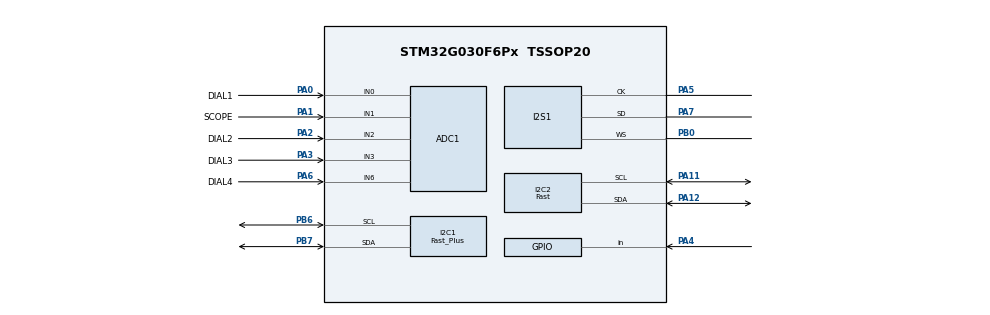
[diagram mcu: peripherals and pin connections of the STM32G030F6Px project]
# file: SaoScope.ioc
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ADC1.ClockPrescaler=ADC_CLOCK_ASYNC_DIV2
ADC1.ContinuousConvMode=ENABLE
ADC1.DMAContinuousRequests=ENABLE
ADC1.EnableAnalogWatchDog1=true
ADC1.EnableAnalogWatchDog2=true
ADC1.NbrOfConversion=1
ADC1.NbrOfConversionFlag=0
ADC1.SamplingTimeCommon1=ADC_SAMPLETIME_7CYCLES_5
ADC1.SelectedChannel=ADC_CHANNEL_0|ADC_CHANNEL_1|ADC_CHANNEL_2|ADC_CHANNEL_3|ADC_CHANNEL_6|ADC_CHANNEL_VREFINT
ADC1.Sequencer=NOT_FULLY_CONFIGURABLE
ADC1.WatchdogChannel=ADC_CHANNEL_1
ADC1.master=1
Dma.ADC1.0.Direction=DMA_PERIPH_TO_MEMORY
Dma.ADC1.0.EventEnable=DISABLE
Dma.ADC1.0.Instance=DMA1_Channel1
Dma.ADC1.0.MemDataAlignment=DMA_MDATAALIGN_HALFWORD
Dma.ADC1.0.MemInc=DMA_MINC_ENABLE
Dma.ADC1.0.Mode=DMA_CIRCULAR
Dma.ADC1.0.PeriphDataAlignment=DMA_PDATAALIGN_HALFWORD
Dma.ADC1.0.PeriphInc=DMA_PINC_DISABLE
Dma.ADC1.0.Polarity=HAL_DMAMUX_REQ_GEN_RISING
Dma.ADC1.0.Priority=DMA_PRIORITY_LOW
Dma.ADC1.0.RequestNumber=1
Dma.ADC1.0.SignalID=NONE
Dma.ADC1.0.SyncEnable=DISABLE
Dma.ADC1.0.SyncPolarity=HAL_DMAMUX_SYNC_NO_EVENT
Dma.ADC1.0.SyncRequestNumber=1
Dma.ADC1.0.SyncSignalID=NONE
Dma.Request0=ADC1
I2C1.I2C_Speed_Mode=I2C_Fast_Plus
I2C1.Timing=0x00200923
I2C2.I2C_Speed_Mode=I2C_Fast
I2C2.OwnAddress=89
I2C2.Timing=0x00501D63
I2S1.AudioFreq=I2S_AUDIOFREQ_192K
I2S1.DataFormat=I2S_DATAFORMAT_32B
I2S1.ErrorAudioFreq=-8.85 %
I2S1.FullDuplexMode=I2S_FULLDUPLEXMODE_DISABLE
I2S1.Instance=SPI$Index
I2S1.Mode=I2S_MODE_MASTER_RX
I2S1.RealAudioFreq=175.0 KHz
I2S1.VirtualMode=I2S_MODE_MASTER
Mcu.Family=STM32G0
Mcu.Name=STM32G030F6Px
Mcu.Package=TSSOP20
NVIC.DMA1_Channel1_IRQn=true\:0\:0\:false\:false\:true\:false\:true\:true
NVIC.RTC_TAMP_IRQn=true\:0\:0\:false\:false\:true\:true\:true\:true
PA0.GPIO_Label=DIAL1
PA0.Mode=IN0
PA0.Signal=ADC1_IN0
PA1.GPIO_Label=SCOPE
PA1.Mode=IN1
PA1.Signal=ADC1_IN1
PA11\ [PA9].Mode=I2C
PA11\ [PA9].Signal=I2C2_SCL
PA12\ [PA10].Mode=I2C
PA12\ [PA10].Signal=I2C2_SDA
PA13.Mode=Serial_Wire
PA13.Signal=SYS_SWDIO
PA14-BOOT0.Mode=Serial_Wire
PA14-BOOT0.Signal=SYS_SWCLK
PA14-BOOT0__PA15.StandardMode=true
PA2.GPIO_Label=DIAL2
PA2.Mode=IN2
PA2.Signal=ADC1_IN2
PA3.GPIO_Label=DIAL3
PA3.Mode=IN3
PA3.Signal=ADC1_IN3
PA4.Signal=GPIO_Input
PA5.Mode=Half_Duplex_Master
PA5.Signal=I2S1_CK
PA6.GPIO_Label=DIAL4
PA6.Mode=IN6
PA6.Signal=ADC1_IN6
PA7.GPIO_Speed=GPIO_SPEED_FREQ_VERY_HIGH
PA7.Signal=SharedStack_PA7
PA7.Stacked=true
PB0.Mode=Half_Duplex_Master
PB0.Signal=I2S1_WS
PB0__PB1__PB2__PA8.StandardMode=true
PB3__PB4__PB5__PB6.StandardMode=true
PB6.GPIO_FM6=SYSCFG_FASTMODEPLUS_PB6
PB6.GPIO_Speed=GPIO_SPEED_FREQ_VERY_HIGH
PB6.Mode=I2C
PB6.Signal=I2C1_SCL
PB7.GPIO_FM7=SYSCFG_FASTMODEPLUS_PB7
PB7.GPIO_Speed=GPIO_SPEED_FREQ_VERY_HIGH
PB7.Mode=I2C
PB7.Signal=I2C1_SDA
PB7__PB8.StandardMode=true
PC14-OSC32_IN\ (PC14).Mode=LSE-External-Oscillator
PC14-OSC32_IN\ (PC14).Signal=RCC_OSC32_IN
PC14-OSC32_IN\ (PC14)__PB9.StandardMode=true
PC15-OSC32_OUT\ (PC15).Mode=LSE-External-Oscillator
PC15-OSC32_OUT\ (PC15).Signal=RCC_OSC32_OUT
ProjectManager.HeapSize=0x000
ProjectManager.StackSize=0x400
ProjectManager.TargetToolchain=CMake
RCC.ADCCLockSelection=RCC_ADCCLKSOURCE_PLLADC
RCC.ADCFreq_Value=70000000
RCC.AHBFreq_Value=56000000
RCC.CortexFreq_Value=56000000
RCC.EXTERNAL_CLOCK_VALUE=12288000
RCC.HCLKFreq_Value=56000000
RCC.HSE_VALUE=8000000
RCC.HSI_VALUE=16000000
RCC.PLLM=RCC_PLLM_DIV4
RCC.PLLN=70
RCC.PLLP=RCC_PLLP_DIV4
RCC.PLLR=RCC_PLLR_DIV5
RCC.RTCClockSelection=RCC_RTCCLKSOURCE_LSE
RCC.SYSCLKFreq_VALUE=56000000
RCC.SYSCLKSource=RCC_SYSCLKSOURCE_PLLCLK
RCC.VCOOutputFreq_Value=280000000
RCC.VDD_VALUE=3
RTC.WakeUpClock-WakeUp=RTC_WAKEUPCLOCK_CK_SPRE_16BITS
RTC.WakeUpCounter-WakeUp=1
SH.SharedStack_PA7.0=TIM17_CH1
SH.SharedStack_PA7.1=I2S1_SD,Half_Duplex_Master
TIM17.Channel=TIM_CHANNEL_1
VP_ADC1_Vref_Input.Mode=IN-Vrefint
VP_RTC_VS_RTC_Activate.Mode=RTC_Enabled
VP_RTC_VS_RTC_WakeUp_intern.Mode=WakeUp
VP_TIM14_VS_ClockSourceINT.Mode=Enable_Timer
VP_TIM16_VS_ClockSourceINT.Mode=Enable_Timer
VP_TIM17_VS_ClockSourceINT.Mode=Enable_Timer
VP_TIM1_VS_ClockSourceINT.Mode=Internal
VP_TIM3_VS_ClockSourceINT.Mode=Internal
board=custom

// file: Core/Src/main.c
/* USER CODE BEGIN Header */
/**
  ******************************************************************************
  * @file           : main.c
  * @brief          : Main program body
  ******************************************************************************
  * @attention
  *
  * Copyright (c) 2022 STMicroelectronics.
  * All rights reserved.
  *
  * This software is licensed under terms that can be found in the LICENSE file
  * in the root directory of this software component.
  * If no LICENSE file comes with this software, it is provided AS-IS.
  *
  ******************************************************************************
  */
/* USER CODE END Header */
#include "main.h"

/* USER CODE BEGIN Includes */

void run();

/* USER CODE END Includes */

void SystemClock_Config(void);
static void MX_GPIO_Init(void);
static void MX_DMA_Init(void);
static void MX_ADC1_Init(void);
static void MX_I2C1_Init(void);
static void MX_I2C2_Init(void);
static void MX_RTC_Init(void);
static void MX_TIM1_Init(void);
static void MX_TIM3_Init(void);
static void MX_TIM14_Init(void);
static void MX_TIM16_Init(void);
static void MX_TIM17_Init(void);
static void MX_I2S1_Init(void);

int main(void)
{

  /* MCU Configuration--------------------------------------------------------*/

  /* Reset of all peripherals, Initializes the Flash interface and the Systick. */
  LL_APB2_GRP1_EnableClock(LL_APB2_GRP1_PERIPH_SYSCFG);
  LL_APB1_GRP1_EnableClock(LL_APB1_GRP1_PERIPH_PWR);

  /* SysTick_IRQn interrupt configuration */
  NVIC_SetPriority(SysTick_IRQn, 3);

  /* Configure the system clock */
  SystemClock_Config();

  /* Initialize all configured peripherals */
  MX_GPIO_Init();
  MX_DMA_Init();
  MX_ADC1_Init();
  MX_I2C1_Init();
  MX_I2C2_Init();
  MX_RTC_Init();
  MX_TIM1_Init();
  MX_TIM3_Init();
  MX_TIM14_Init();
  MX_TIM16_Init();
  MX_TIM17_Init();
  MX_I2S1_Init();

  /* Infinite loop */
  /* USER CODE BEGIN WHILE */
  run();
    /* USER CODE END WHILE */

}

void SystemClock_Config(void)
{
  LL_FLASH_SetLatency(LL_FLASH_LATENCY_2);
  while(LL_FLASH_GetLatency() != LL_FLASH_LATENCY_2)
  {
  }

  /* HSI configuration and activation */
  LL_RCC_HSI_Enable();
  while(LL_RCC_HSI_IsReady() != 1)
  {
  }

  LL_PWR_EnableBkUpAccess();
  /* LSE configuration and activation */
  LL_RCC_LSE_SetDriveCapability(LL_RCC_LSEDRIVE_LOW);
  LL_RCC_LSE_Enable();
  while(LL_RCC_LSE_IsReady() != 1)
  {
  }

  /* Main PLL configuration and activation */
  LL_RCC_PLL_ConfigDomain_ADC(LL_RCC_PLLSOURCE_HSI, LL_RCC_PLLM_DIV_4, 70, LL_RCC_PLLP_DIV_4);
  LL_RCC_PLL_EnableDomain_ADC();
  LL_RCC_PLL_ConfigDomain_SYS(LL_RCC_PLLSOURCE_HSI, LL_RCC_PLLM_DIV_4, 70, LL_RCC_PLLR_DIV_5);
  LL_RCC_PLL_Enable();
  LL_RCC_PLL_EnableDomain_SYS();
  while(LL_RCC_PLL_IsReady() != 1)
  {
  }

  /* Set AHB prescaler*/
  LL_RCC_SetAHBPrescaler(LL_RCC_SYSCLK_DIV_1);

  /* Sysclk activation on the main PLL */
  LL_RCC_SetSysClkSource(LL_RCC_SYS_CLKSOURCE_PLL);
  while(LL_RCC_GetSysClkSource() != LL_RCC_SYS_CLKSOURCE_STATUS_PLL)
  {
  }

  /* Set APB1 prescaler*/
  LL_RCC_SetAPB1Prescaler(LL_RCC_APB1_DIV_1);

  LL_Init1msTick(56000000);

  /* Update CMSIS variable (which can be updated also through SystemCoreClockUpdate function) */
  LL_SetSystemCoreClock(56000000);
}

static void MX_ADC1_Init(void)
{

  LL_ADC_InitTypeDef ADC_InitStruct = {0};
  LL_ADC_REG_InitTypeDef ADC_REG_InitStruct = {0};

  LL_GPIO_InitTypeDef GPIO_InitStruct = {0};

  LL_RCC_SetADCClockSource(LL_RCC_ADC_CLKSOURCE_PLL);

  /* Peripheral clock enable */
  LL_APB2_GRP1_EnableClock(LL_APB2_GRP1_PERIPH_ADC);

  LL_IOP_GRP1_EnableClock(LL_IOP_GRP1_PERIPH_GPIOA);
  /**ADC1 GPIO Configuration
  PA0   ------> ADC1_IN0
  PA1   ------> ADC1_IN1
  PA2   ------> ADC1_IN2
  PA3   ------> ADC1_IN3
  PA6   ------> ADC1_IN6
  */
  GPIO_InitStruct.Pin = DIAL1_Pin;
  GPIO_InitStruct.Mode = LL_GPIO_MODE_ANALOG;
  GPIO_InitStruct.Pull = LL_GPIO_PULL_NO;
  LL_GPIO_Init(DIAL1_GPIO_Port, &GPIO_InitStruct);

  GPIO_InitStruct.Pin = SCOPE_Pin;
  GPIO_InitStruct.Mode = LL_GPIO_MODE_ANALOG;
  GPIO_InitStruct.Pull = LL_GPIO_PULL_NO;
  LL_GPIO_Init(SCOPE_GPIO_Port, &GPIO_InitStruct);

  GPIO_InitStruct.Pin = DIAL2_Pin;
  GPIO_InitStruct.Mode = LL_GPIO_MODE_ANALOG;
  GPIO_InitStruct.Pull = LL_GPIO_PULL_NO;
  LL_GPIO_Init(DIAL2_GPIO_Port, &GPIO_InitStruct);

  GPIO_InitStruct.Pin = DIAL3_Pin;
  GPIO_InitStruct.Mode = LL_GPIO_MODE_ANALOG;
  GPIO_InitStruct.Pull = LL_GPIO_PULL_NO;
  LL_GPIO_Init(DIAL3_GPIO_Port, &GPIO_InitStruct);

  GPIO_InitStruct.Pin = DIAL4_Pin;
  GPIO_InitStruct.Mode = LL_GPIO_MODE_ANALOG;
  GPIO_InitStruct.Pull = LL_GPIO_PULL_NO;
  LL_GPIO_Init(DIAL4_GPIO_Port, &GPIO_InitStruct);

  /* ADC1 DMA Init */

  /* ADC1 Init */
  LL_DMA_SetPeriphRequest(DMA1, LL_DMA_CHANNEL_1, LL_DMAMUX_REQ_ADC1);

  LL_DMA_SetDataTransferDirection(DMA1, LL_DMA_CHANNEL_1, LL_DMA_DIRECTION_PERIPH_TO_MEMORY);

  LL_DMA_SetChannelPriorityLevel(DMA1, LL_DMA_CHANNEL_1, LL_DMA_PRIORITY_LOW);

  LL_DMA_SetMode(DMA1, LL_DMA_CHANNEL_1, LL_DMA_MODE_CIRCULAR);

  LL_DMA_SetPeriphIncMode(DMA1, LL_DMA_CHANNEL_1, LL_DMA_PERIPH_NOINCREMENT);

  LL_DMA_SetMemoryIncMode(DMA1, LL_DMA_CHANNEL_1, LL_DMA_MEMORY_INCREMENT);

  LL_DMA_SetPeriphSize(DMA1, LL_DMA_CHANNEL_1, LL_DMA_PDATAALIGN_HALFWORD);

  LL_DMA_SetMemorySize(DMA1, LL_DMA_CHANNEL_1, LL_DMA_MDATAALIGN_HALFWORD);

  /** Configure the global features of the ADC (Clock, Resolution, Data Alignment and number of conversion)
  */

   #define ADC_CHANNEL_CONF_RDY_TIMEOUT_MS ( 1U)
   #if (USE_TIMEOUT == 1)
   uint32_t Timeout ; /* Variable used for Timeout management */
   #endif /* USE_TIMEOUT */

  ADC_InitStruct.Resolution = LL_ADC_RESOLUTION_12B;
  ADC_InitStruct.DataAlignment = LL_ADC_DATA_ALIGN_RIGHT;
  ADC_InitStruct.LowPowerMode = LL_ADC_LP_MODE_NONE;
  LL_ADC_Init(ADC1, &ADC_InitStruct);
  LL_ADC_REG_SetSequencerConfigurable(ADC1, LL_ADC_REG_SEQ_FIXED);
  ADC_REG_InitStruct.TriggerSource = LL_ADC_REG_TRIG_SOFTWARE;
  ADC_REG_InitStruct.SequencerLength = LL_ADC_REG_SEQ_SCAN_DISABLE;
  ADC_REG_InitStruct.ContinuousMode = LL_ADC_REG_CONV_CONTINUOUS;
  ADC_REG_InitStruct.DMATransfer = LL_ADC_REG_DMA_TRANSFER_UNLIMITED;
  ADC_REG_InitStruct.Overrun = LL_ADC_REG_OVR_DATA_PRESERVED;
  LL_ADC_REG_Init(ADC1, &ADC_REG_InitStruct);
  LL_ADC_SetCommonClock(__LL_ADC_COMMON_INSTANCE(ADC1), LL_ADC_CLOCK_ASYNC_DIV2);
  LL_ADC_REG_SetSequencerScanDirection(ADC1, LL_ADC_REG_SEQ_SCAN_DIR_FORWARD);
  LL_ADC_SetOverSamplingScope(ADC1, LL_ADC_OVS_DISABLE);
  LL_ADC_SetTriggerFrequencyMode(ADC1, LL_ADC_CLOCK_FREQ_MODE_HIGH);
  LL_ADC_REG_SetSequencerChAdd(ADC1, LL_ADC_CHANNEL_0|LL_ADC_CHANNEL_1
                              |LL_ADC_CHANNEL_2|LL_ADC_CHANNEL_3
                              |LL_ADC_CHANNEL_6|LL_ADC_CHANNEL_VREFINT);

   /* Poll for ADC channel configuration ready */
   #if (USE_TIMEOUT == 1)
   Timeout = ADC_CHANNEL_CONF_RDY_TIMEOUT_MS;
   #endif /* USE_TIMEOUT */
   while (LL_ADC_IsActiveFlag_CCRDY(ADC1) == 0)
     {
   #if (USE_TIMEOUT == 1)
   /* Check Systick counter flag to decrement the time-out value */
   if (LL_SYSTICK_IsActiveCounterFlag())
     {
   if(Timeout-- == 0)
         {
   Error_Handler();
         }
     }
   #endif /* USE_TIMEOUT */
     }
   /* Clear flag ADC channel configuration ready */
   LL_ADC_ClearFlag_CCRDY(ADC1);
  LL_ADC_SetCommonPathInternalCh(__LL_ADC_COMMON_INSTANCE(ADC1), LL_ADC_AWD_CH_VREFINT_REG);
  LL_ADC_SetSamplingTimeCommonChannels(ADC1, LL_ADC_SAMPLINGTIME_COMMON_1, LL_ADC_SAMPLINGTIME_7CYCLES_5);
  LL_ADC_DisableIT_EOC(ADC1);
  LL_ADC_DisableIT_EOS(ADC1);

   /* Enable ADC internal voltage regulator */
   LL_ADC_EnableInternalRegulator(ADC1);
   /* Delay for ADC internal voltage regulator stabilization. */
   /* Compute number of CPU cycles to wait for, from delay in us. */
   /* Note: Variable divided by 2 to compensate partially */
   /* CPU processing cycles (depends on compilation optimization). */
   /* Note: If system core clock frequency is below 200kHz, wait time */
   /* is only a few CPU processing cycles. */
   uint32_t wait_loop_index;
   wait_loop_index = ((LL_ADC_DELAY_INTERNAL_REGUL_STAB_US * (SystemCoreClock / (100000 * 2))) / 10);
   while(wait_loop_index != 0)
     {
   wait_loop_index--;
     }

  /** Configure Analog WatchDog 1
  */
  LL_ADC_SetAnalogWDMonitChannels(ADC1, LL_ADC_AWD1, LL_ADC_AWD_CHANNEL_1_REG);
  LL_ADC_ConfigAnalogWDThresholds(ADC1, LL_ADC_AWD1, 0, 0);
  LL_ADC_DisableIT_AWD1(ADC1);

  /** Configure the regular channel to be monitored by WatchDog 2
  */
  LL_ADC_ConfigAnalogWDThresholds(ADC1, LL_ADC_AWD2, 0, 0);
  LL_ADC_DisableIT_AWD2(ADC1);

}

static void MX_I2C1_Init(void)
{

  LL_I2C_InitTypeDef I2C_InitStruct = {0};

  LL_GPIO_InitTypeDef GPIO_InitStruct = {0};

  LL_RCC_SetI2CClockSource(LL_RCC_I2C1_CLKSOURCE_PCLK1);

  LL_IOP_GRP1_EnableClock(LL_IOP_GRP1_PERIPH_GPIOB);
  /**I2C1 GPIO Configuration
  PB7   ------> I2C1_SDA
  PB6   ------> I2C1_SCL
  */
  GPIO_InitStruct.Pin = LL_GPIO_PIN_7;
  GPIO_InitStruct.Mode = LL_GPIO_MODE_ALTERNATE;
  GPIO_InitStruct.Speed = LL_GPIO_SPEED_FREQ_VERY_HIGH;
  GPIO_InitStruct.OutputType = LL_GPIO_OUTPUT_OPENDRAIN;
  GPIO_InitStruct.Pull = LL_GPIO_PULL_NO;
  GPIO_InitStruct.Alternate = LL_GPIO_AF_6;
  LL_GPIO_Init(GPIOB, &GPIO_InitStruct);

  GPIO_InitStruct.Pin = LL_GPIO_PIN_6;
  GPIO_InitStruct.Mode = LL_GPIO_MODE_ALTERNATE;
  GPIO_InitStruct.Speed = LL_GPIO_SPEED_FREQ_VERY_HIGH;
  GPIO_InitStruct.OutputType = LL_GPIO_OUTPUT_OPENDRAIN;
  GPIO_InitStruct.Pull = LL_GPIO_PULL_NO;
  GPIO_InitStruct.Alternate = LL_GPIO_AF_6;
  LL_GPIO_Init(GPIOB, &GPIO_InitStruct);

  LL_SYSCFG_EnableFastModePlus(LL_SYSCFG_I2C_FASTMODEPLUS_PB7);

  LL_SYSCFG_EnableFastModePlus(LL_SYSCFG_I2C_FASTMODEPLUS_PB6);

  /* Peripheral clock enable */
  LL_APB1_GRP1_EnableClock(LL_APB1_GRP1_PERIPH_I2C1);

  /** I2C Initialization
  */
  I2C_InitStruct.PeripheralMode = LL_I2C_MODE_I2C;
  I2C_InitStruct.Timing = 0x00200923;
  I2C_InitStruct.AnalogFilter = LL_I2C_ANALOGFILTER_ENABLE;
  I2C_InitStruct.DigitalFilter = 0;
  I2C_InitStruct.OwnAddress1 = 0;
  I2C_InitStruct.TypeAcknowledge = LL_I2C_ACK;
  I2C_InitStruct.OwnAddrSize = LL_I2C_OWNADDRESS1_7BIT;
  LL_I2C_Init(I2C1, &I2C_InitStruct);
  LL_I2C_EnableAutoEndMode(I2C1);
  LL_I2C_SetOwnAddress2(I2C1, 0, LL_I2C_OWNADDRESS2_NOMASK);
  LL_I2C_DisableOwnAddress2(I2C1);
  LL_I2C_DisableGeneralCall(I2C1);
  LL_I2C_EnableClockStretching(I2C1);

  /** I2C Fast mode Plus enable
  */
  LL_SYSCFG_EnableFastModePlus(LL_SYSCFG_I2C_FASTMODEPLUS_I2C1);

}

static void MX_I2C2_Init(void)
{

  LL_I2C_InitTypeDef I2C_InitStruct = {0};

  LL_GPIO_InitTypeDef GPIO_InitStruct = {0};

  LL_IOP_GRP1_EnableClock(LL_IOP_GRP1_PERIPH_GPIOA);
  /**I2C2 GPIO Configuration
  PA11 [PA9]   ------> I2C2_SCL
  PA12 [PA10]   ------> I2C2_SDA
  */
  GPIO_InitStruct.Pin = LL_GPIO_PIN_11;
  GPIO_InitStruct.Mode = LL_GPIO_MODE_ALTERNATE;
  GPIO_InitStruct.Speed = LL_GPIO_SPEED_FREQ_LOW;
  GPIO_InitStruct.OutputType = LL_GPIO_OUTPUT_OPENDRAIN;
  GPIO_InitStruct.Pull = LL_GPIO_PULL_NO;
  GPIO_InitStruct.Alternate = LL_GPIO_AF_6;
  LL_GPIO_Init(GPIOA, &GPIO_InitStruct);

  GPIO_InitStruct.Pin = LL_GPIO_PIN_12;
  GPIO_InitStruct.Mode = LL_GPIO_MODE_ALTERNATE;
  GPIO_InitStruct.Speed = LL_GPIO_SPEED_FREQ_LOW;
  GPIO_InitStruct.OutputType = LL_GPIO_OUTPUT_OPENDRAIN;
  GPIO_InitStruct.Pull = LL_GPIO_PULL_NO;
  GPIO_InitStruct.Alternate = LL_GPIO_AF_6;
  LL_GPIO_Init(GPIOA, &GPIO_InitStruct);

  /* Peripheral clock enable */
  LL_APB1_GRP1_EnableClock(LL_APB1_GRP1_PERIPH_I2C2);

  /** I2C Initialization
  */
  I2C_InitStruct.PeripheralMode = LL_I2C_MODE_I2C;
  I2C_InitStruct.Timing = 0x00501D63;
  I2C_InitStruct.AnalogFilter = LL_I2C_ANALOGFILTER_ENABLE;
  I2C_InitStruct.DigitalFilter = 0;
  I2C_InitStruct.OwnAddress1 = 178;
  I2C_InitStruct.TypeAcknowledge = LL_I2C_ACK;
  I2C_InitStruct.OwnAddrSize = LL_I2C_OWNADDRESS1_7BIT;
  LL_I2C_Init(I2C2, &I2C_InitStruct);
  LL_I2C_EnableAutoEndMode(I2C2);
  LL_I2C_SetOwnAddress2(I2C2, 0, LL_I2C_OWNADDRESS2_NOMASK);
  LL_I2C_DisableOwnAddress2(I2C2);
  LL_I2C_DisableGeneralCall(I2C2);
  LL_I2C_EnableClockStretching(I2C2);

}

static void MX_I2S1_Init(void)
{

  LL_I2S_InitTypeDef I2S_InitStruct = {0};

  LL_GPIO_InitTypeDef GPIO_InitStruct = {0};

  LL_RCC_SetI2SClockSource(LL_RCC_I2S1_CLKSOURCE_SYSCLK);

  /* Peripheral clock enable */
  LL_APB2_GRP1_EnableClock(LL_APB2_GRP1_PERIPH_SPI1);

  LL_IOP_GRP1_EnableClock(LL_IOP_GRP1_PERIPH_GPIOA);
  LL_IOP_GRP1_EnableClock(LL_IOP_GRP1_PERIPH_GPIOB);
  /**I2S1 GPIO Configuration
  PA5   ------> I2S1_CK
  PA7   ------> I2S1_SD
  PB0   ------> I2S1_WS
  */
  GPIO_InitStruct.Pin = LL_GPIO_PIN_5;
  GPIO_InitStruct.Mode = LL_GPIO_MODE_ALTERNATE;
  GPIO_InitStruct.Speed = LL_GPIO_SPEED_FREQ_LOW;
  GPIO_InitStruct.OutputType = LL_GPIO_OUTPUT_PUSHPULL;
  GPIO_InitStruct.Pull = LL_GPIO_PULL_NO;
  GPIO_InitStruct.Alternate = LL_GPIO_AF_0;
  LL_GPIO_Init(GPIOA, &GPIO_InitStruct);

  GPIO_InitStruct.Pin = LL_GPIO_PIN_7;
  GPIO_InitStruct.Mode = LL_GPIO_MODE_ALTERNATE;
  GPIO_InitStruct.Speed = LL_GPIO_SPEED_FREQ_VERY_HIGH;
  GPIO_InitStruct.OutputType = LL_GPIO_OUTPUT_PUSHPULL;
  GPIO_InitStruct.Pull = LL_GPIO_PULL_NO;
  GPIO_InitStruct.Alternate = LL_GPIO_AF_0;
  LL_GPIO_Init(GPIOA, &GPIO_InitStruct);

  GPIO_InitStruct.Pin = LL_GPIO_PIN_0;
  GPIO_InitStruct.Mode = LL_GPIO_MODE_ALTERNATE;
  GPIO_InitStruct.Speed = LL_GPIO_SPEED_FREQ_LOW;
  GPIO_InitStruct.OutputType = LL_GPIO_OUTPUT_PUSHPULL;
  GPIO_InitStruct.Pull = LL_GPIO_PULL_NO;
  GPIO_InitStruct.Alternate = LL_GPIO_AF_0;
  LL_GPIO_Init(GPIOB, &GPIO_InitStruct);

  I2S_InitStruct.Mode = LL_I2S_MODE_MASTER_RX;
  I2S_InitStruct.Standard = LL_I2S_STANDARD_PHILIPS;
  I2S_InitStruct.DataFormat = LL_I2S_DATAFORMAT_32B;
  I2S_InitStruct.MCLKOutput = LL_I2S_MCLK_OUTPUT_DISABLE;
  I2S_InitStruct.AudioFreq = LL_I2S_AUDIOFREQ_192K;
  I2S_InitStruct.ClockPolarity = LL_I2S_POLARITY_LOW;
  LL_I2S_Init(SPI1, &I2S_InitStruct);

}

static void MX_RTC_Init(void)
{

  LL_RTC_InitTypeDef RTC_InitStruct = {0};

  if(LL_RCC_GetRTCClockSource() != LL_RCC_RTC_CLKSOURCE_LSE)
  {
    FlagStatus pwrclkchanged = RESET;
    /* Update LSE configuration in Backup Domain control register */
    /* Requires to enable write access to Backup Domain if necessary */
    if (LL_APB1_GRP1_IsEnabledClock (LL_APB1_GRP1_PERIPH_PWR) != 1U)
    {
      /* Enables the PWR Clock and Enables access to the backup domain */
      LL_APB1_GRP1_EnableClock(LL_APB1_GRP1_PERIPH_PWR);
      pwrclkchanged = SET;
    }
    if (LL_PWR_IsEnabledBkUpAccess () != 1U)
    {
      /* Enable write access to Backup domain */
      LL_PWR_EnableBkUpAccess();
      while (LL_PWR_IsEnabledBkUpAccess () == 0U)
      {
      }
    }
    LL_RCC_ForceBackupDomainReset();
    LL_RCC_ReleaseBackupDomainReset();
  LL_RCC_LSE_SetDriveCapability(LL_RCC_LSEDRIVE_LOW);
    LL_RCC_LSE_Enable();

   /* Wait till LSE is ready */
    while(LL_RCC_LSE_IsReady() != 1)
    {
    }
    LL_RCC_SetRTCClockSource(LL_RCC_RTC_CLKSOURCE_LSE);
    /* Restore clock configuration if changed */
    if (pwrclkchanged == SET)
    {
      LL_APB1_GRP1_DisableClock(LL_APB1_GRP1_PERIPH_PWR);
    }
  }

  /* Peripheral clock enable */
  LL_RCC_EnableRTC();
  LL_APB1_GRP1_EnableClock(LL_APB1_GRP1_PERIPH_RTC);

  /* RTC interrupt Init */
  NVIC_SetPriority(RTC_TAMP_IRQn, 0);
  NVIC_EnableIRQ(RTC_TAMP_IRQn);

  RTC_InitStruct.HourFormat = LL_RTC_HOURFORMAT_24HOUR;
  RTC_InitStruct.AsynchPrescaler = 127;
  RTC_InitStruct.SynchPrescaler = 255;
  LL_RTC_Init(RTC, &RTC_InitStruct);

  /** Enable the WakeUp
  */
  LL_RTC_EnableIT_WUT(RTC);
  LL_RTC_WAKEUP_SetClock(RTC, LL_RTC_WAKEUPCLOCK_CKSPRE);
  LL_RTC_WAKEUP_SetAutoReload(RTC, 1);

}

static void MX_TIM1_Init(void)
{

  LL_TIM_InitTypeDef TIM_InitStruct = {0};

  /* Peripheral clock enable */
  LL_APB2_GRP1_EnableClock(LL_APB2_GRP1_PERIPH_TIM1);

  TIM_InitStruct.Prescaler = 0;
  TIM_InitStruct.CounterMode = LL_TIM_COUNTERMODE_UP;
  TIM_InitStruct.Autoreload = 65535;
  TIM_InitStruct.ClockDivision = LL_TIM_CLOCKDIVISION_DIV1;
  TIM_InitStruct.RepetitionCounter = 0;
  LL_TIM_Init(TIM1, &TIM_InitStruct);
  LL_TIM_DisableARRPreload(TIM1);
  LL_TIM_SetClockSource(TIM1, LL_TIM_CLOCKSOURCE_INTERNAL);
  LL_TIM_SetTriggerOutput(TIM1, LL_TIM_TRGO_RESET);
  LL_TIM_SetTriggerOutput2(TIM1, LL_TIM_TRGO2_RESET);
  LL_TIM_DisableMasterSlaveMode(TIM1);

}

static void MX_TIM3_Init(void)
{

  LL_TIM_InitTypeDef TIM_InitStruct = {0};

  /* Peripheral clock enable */
  LL_APB1_GRP1_EnableClock(LL_APB1_GRP1_PERIPH_TIM3);

  TIM_InitStruct.Prescaler = 0;
  TIM_InitStruct.CounterMode = LL_TIM_COUNTERMODE_UP;
  TIM_InitStruct.Autoreload = 65535;
  TIM_InitStruct.ClockDivision = LL_TIM_CLOCKDIVISION_DIV1;
  LL_TIM_Init(TIM3, &TIM_InitStruct);
  LL_TIM_DisableARRPreload(TIM3);
  LL_TIM_SetClockSource(TIM3, LL_TIM_CLOCKSOURCE_INTERNAL);
  LL_TIM_SetTriggerOutput(TIM3, LL_TIM_TRGO_RESET);
  LL_TIM_DisableMasterSlaveMode(TIM3);

}

static void MX_TIM14_Init(void)
{

  LL_TIM_InitTypeDef TIM_InitStruct = {0};

  /* Peripheral clock enable */
  LL_APB2_GRP1_EnableClock(LL_APB2_GRP1_PERIPH_TIM14);

  TIM_InitStruct.Prescaler = 0;
  TIM_InitStruct.CounterMode = LL_TIM_COUNTERMODE_UP;
  TIM_InitStruct.Autoreload = 65535;
  TIM_InitStruct.ClockDivision = LL_TIM_CLOCKDIVISION_DIV1;
  LL_TIM_Init(TIM14, &TIM_InitStruct);
  LL_TIM_DisableARRPreload(TIM14);

}

static void MX_TIM16_Init(void)
{

  LL_TIM_InitTypeDef TIM_InitStruct = {0};

  /* Peripheral clock enable */
  LL_APB2_GRP1_EnableClock(LL_APB2_GRP1_PERIPH_TIM16);

  TIM_InitStruct.Prescaler = 0;
  TIM_InitStruct.CounterMode = LL_TIM_COUNTERMODE_UP;
  TIM_InitStruct.Autoreload = 65535;
  TIM_InitStruct.ClockDivision = LL_TIM_CLOCKDIVISION_DIV1;
  TIM_InitStruct.RepetitionCounter = 0;
  LL_TIM_Init(TIM16, &TIM_InitStruct);
  LL_TIM_DisableARRPreload(TIM16);

}

static void MX_TIM17_Init(void)
{

  LL_TIM_InitTypeDef TIM_InitStruct = {0};

  /* Peripheral clock enable */
  LL_APB2_GRP1_EnableClock(LL_APB2_GRP1_PERIPH_TIM17);

  TIM_InitStruct.Prescaler = 0;
  TIM_InitStruct.CounterMode = LL_TIM_COUNTERMODE_UP;
  TIM_InitStruct.Autoreload = 65535;
  TIM_InitStruct.ClockDivision = LL_TIM_CLOCKDIVISION_DIV1;
  TIM_InitStruct.RepetitionCounter = 0;
  LL_TIM_Init(TIM17, &TIM_InitStruct);
  LL_TIM_DisableARRPreload(TIM17);

}

static void MX_DMA_Init(void)
{

  /* Init with LL driver */
  /* DMA controller clock enable */
  LL_AHB1_GRP1_EnableClock(LL_AHB1_GRP1_PERIPH_DMA1);

  /* DMA interrupt init */
  /* DMA1_Channel1_IRQn interrupt configuration */
  NVIC_SetPriority(DMA1_Channel1_IRQn, 0);
  NVIC_EnableIRQ(DMA1_Channel1_IRQn);

}

static void MX_GPIO_Init(void)
{
  LL_GPIO_InitTypeDef GPIO_InitStruct = {0};

  /* GPIO Ports Clock Enable */
  LL_IOP_GRP1_EnableClock(LL_IOP_GRP1_PERIPH_GPIOB);
  LL_IOP_GRP1_EnableClock(LL_IOP_GRP1_PERIPH_GPIOC);
  LL_IOP_GRP1_EnableClock(LL_IOP_GRP1_PERIPH_GPIOA);

  /**/
  GPIO_InitStruct.Pin = LL_GPIO_PIN_4;
  GPIO_InitStruct.Mode = LL_GPIO_MODE_INPUT;
  GPIO_InitStruct.Pull = LL_GPIO_PULL_NO;
  LL_GPIO_Init(GPIOA, &GPIO_InitStruct);

}

void Error_Handler(void)
{
  __disable_irq();
  while (1)
  {
  }
}
